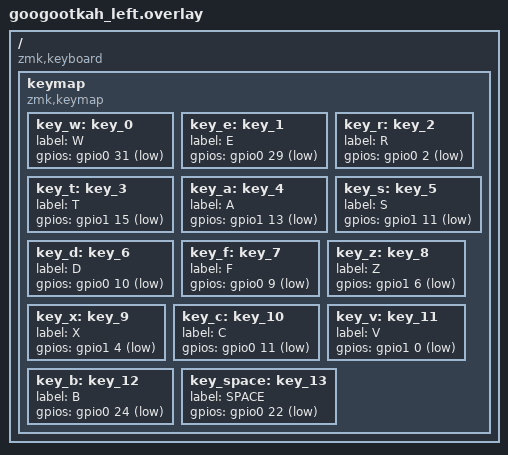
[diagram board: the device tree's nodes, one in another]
/ {
    compatible = "zmk,keyboard";

    keymap {
        compatible = "zmk,keymap";

        // Red 1
        key_w: key_0 { label = "W"; gpios = <&gpio0 31 GPIO_ACTIVE_LOW>; };
        key_e: key_1 { label = "E"; gpios = <&gpio0 29 GPIO_ACTIVE_LOW>; };
        key_r: key_2 { label = "R"; gpios = <&gpio0 2  GPIO_ACTIVE_LOW>; };
        key_t: key_3 { label = "T"; gpios = <&gpio1 15 GPIO_ACTIVE_LOW>; };

        // Red 2
        key_a: key_4 { label = "A"; gpios = <&gpio1 13 GPIO_ACTIVE_LOW>; };
        key_s: key_5 { label = "S"; gpios = <&gpio1 11 GPIO_ACTIVE_LOW>; };
        key_d: key_6 { label = "D"; gpios = <&gpio0 10 GPIO_ACTIVE_LOW>; };
        key_f: key_7 { label = "F"; gpios = <&gpio0 9  GPIO_ACTIVE_LOW>; };

        // Red 3
        key_z: key_8  { label = "Z"; gpios = <&gpio1 6  GPIO_ACTIVE_LOW>; };
        key_x: key_9  { label = "X"; gpios = <&gpio1 4  GPIO_ACTIVE_LOW>; };
        key_c: key_10 { label = "C"; gpios = <&gpio0 11 GPIO_ACTIVE_LOW>; };
        key_v: key_11 { label = "V"; gpios = <&gpio1 0  GPIO_ACTIVE_LOW>; };
        key_b: key_12 { label = "B"; gpios = <&gpio0 24 GPIO_ACTIVE_LOW>; };
        key_space: key_13 { label = "SPACE"; gpios = <&gpio0 22 GPIO_ACTIVE_LOW>; };
    };
};
